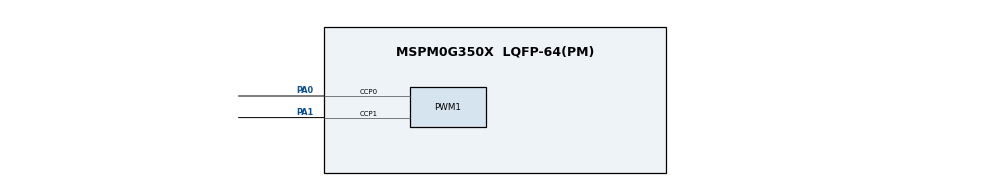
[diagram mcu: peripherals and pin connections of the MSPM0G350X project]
/**
 * @cliArgs --device "MSPM0G350X" --part "Default" --package "LQFP-64(PM)" --product "mspm0_sdk@2.10.00.04"
 * @versions {"tool":"1.27.1+4634"}
 */

/**
 * Import the modules used in this configuration.
 */
const GPIO   = scripting.addModule("/ti/driverlib/GPIO", {}, false);
const GPIO1  = GPIO.addInstance();
const GPIO2  = GPIO.addInstance();
const PWM    = scripting.addModule("/ti/driverlib/PWM", {}, false);
const PWM1   = PWM.addInstance();
const SYSCTL = scripting.addModule("/ti/driverlib/SYSCTL");

/**
 * Write custom configuration values to the imported modules.
 */
GPIO1.$name                          = "MOTOR_DIR1";
GPIO1.associatedPins[0].assignedPort = "PORTB";
GPIO1.associatedPins[0].assignedPin  = "0";
GPIO1.associatedPins[0].$name        = "PIN_26";

const Board = scripting.addModule("/ti/driverlib/Board", {}, false);

GPIO2.$name                          = "MOTOR_DIR2";
GPIO2.associatedPins[0].$name        = "PIN_27";
GPIO2.associatedPins[0].assignedPort = "PORTB";
GPIO2.associatedPins[0].assignedPin  = "8";

PWM1.$name                              = "PWM_FOR_MOTOR";
PWM1.timerCount                         = 2133;
PWM1.timerStartTimer                    = true;
PWM1.pwmMode                            = "EDGE_ALIGN_UP";
PWM1.peripheral.ccp0Pin.$assign         = "PA0";
PWM1.peripheral.ccp1Pin.$assign         = "PA1";
PWM1.PWM_CHANNEL_0.$name                = "ti_driverlib_pwm_PWMTimerCC0";
PWM1.PWM_CHANNEL_1.$name                = "ti_driverlib_pwm_PWMTimerCC1";
PWM1.ccp0PinConfig.$name                = "ti_driverlib_gpio_GPIOPinGeneric0";
PWM1.ccp0PinConfig.direction            = scripting.forceWrite("OUTPUT");
PWM1.ccp0PinConfig.hideOutputInversion  = scripting.forceWrite(false);
PWM1.ccp0PinConfig.onlyInternalResistor = scripting.forceWrite(false);
PWM1.ccp0PinConfig.passedPeripheralType = scripting.forceWrite("Digital");
PWM1.ccp1PinConfig.$name                = "ti_driverlib_gpio_GPIOPinGeneric1";
PWM1.ccp1PinConfig.direction            = scripting.forceWrite("OUTPUT");
PWM1.ccp1PinConfig.hideOutputInversion  = scripting.forceWrite(false);
PWM1.ccp1PinConfig.onlyInternalResistor = scripting.forceWrite(false);
PWM1.ccp1PinConfig.passedPeripheralType = scripting.forceWrite("Digital");

SYSCTL.forceDefaultClkConfig = true;

/**
 * Pinmux solution for unlocked pins/peripherals. This ensures that minor changes to the automatic solver in a future
 * version of the tool will not impact the pinmux you originally saw.  These lines can be completely deleted in order to
 * re-solve from scratch.
 */
GPIO1.associatedPins[0].pin.$suggestSolution = "PB0";
Board.peripheral.$suggestSolution            = "DEBUGSS";
Board.peripheral.swclkPin.$suggestSolution   = "PA20";
Board.peripheral.swdioPin.$suggestSolution   = "PA19";
GPIO2.associatedPins[0].pin.$suggestSolution = "PB8";
PWM1.peripheral.$suggestSolution             = "TIMA0";
SYSCTL.peripheral.$suggestSolution           = "SYSCTL";
